# VPAC0_VISS0_ECC_AGGR_0_IVPAC_TOP_0_CFG_SLV_PAR_VPAC_VISS0_S_VBUSP_KSDW_ECC_AGGR_CFG register map
Vendor: Texas Instruments
Peripheral module from a debugger description file (folder am62A).
Registers are 32-bit, access not given, reset 0x0 unless marked. A register's access mark holds for its fields unless they carry their own. Offsets are as the file gives them; lines under a group give offsets from that group; [hi:lo] are bit positions; {n}, {i} and the like mark numbered series; 'fields as' and 'values as' point back to an identical list; <NAME> marks a mode.

## VPAC0_VISS0_ECC_AGGR_0_IVPAC_TOP_0_CFG_SLV_PAR_VPAC_VISS0_S_VBUSP_KSDW_ECC_AGGR_CFG
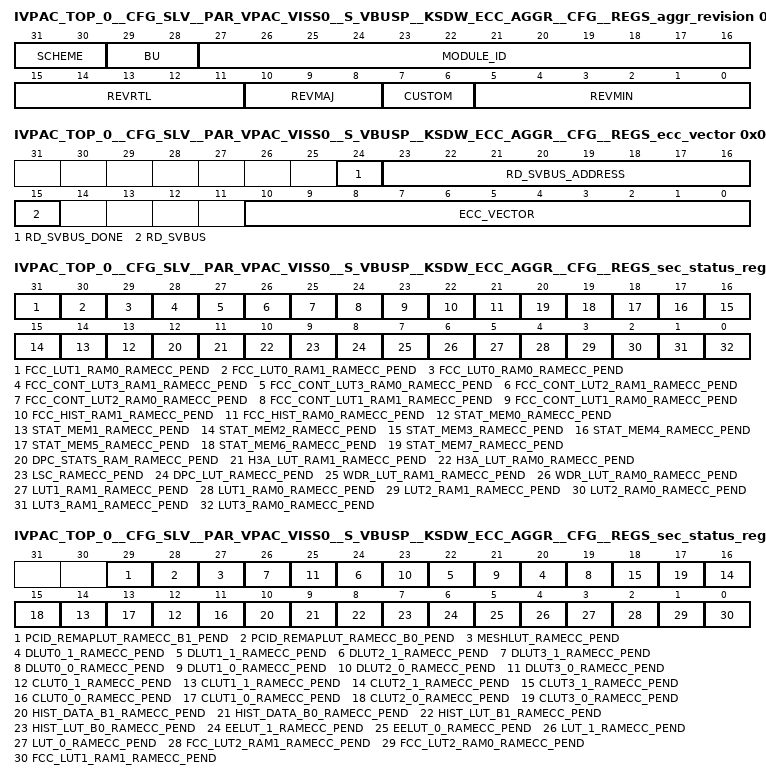
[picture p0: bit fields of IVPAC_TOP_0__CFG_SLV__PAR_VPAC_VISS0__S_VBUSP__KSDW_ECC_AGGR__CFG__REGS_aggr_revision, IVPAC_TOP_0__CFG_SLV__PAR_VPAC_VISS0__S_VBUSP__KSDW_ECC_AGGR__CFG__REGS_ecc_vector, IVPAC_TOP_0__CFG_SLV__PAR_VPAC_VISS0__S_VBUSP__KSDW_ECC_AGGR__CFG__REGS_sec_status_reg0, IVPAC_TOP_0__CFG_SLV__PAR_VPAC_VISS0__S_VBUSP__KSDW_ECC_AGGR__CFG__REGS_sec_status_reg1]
0x00 IVPAC_TOP_0__CFG_SLV__PAR_VPAC_VISS0__S_VBUSP__KSDW_ECC_AGGR__CFG__REGS_aggr_revision ro reset 0x66A03A01 — Revision parameters
  [31:30] SCHEME
  [29:28] BU
  [27:16] MODULE_ID
  [15:11] REVRTL — RTL version
  [10:8] REVMAJ — Major version
  [7:6] CUSTOM — Custom version
  [5:0] REVMIN — Minor version
0x08 IVPAC_TOP_0__CFG_SLV__PAR_VPAC_VISS0__S_VBUSP__KSDW_ECC_AGGR__CFG__REGS_ecc_vector — ECC Vector Register
  [24] RD_SVBUS_DONE — Status to indicate if read on serial VBUS is complete, write of any value will clear this bit. (access R/W1TC)
  [23:16] RD_SVBUS_ADDRESS rw — Read address
  [15] RD_SVBUS — Write 1 to trigger a read on the serial VBUS (access R/W1TS)
  [10:0] ECC_VECTOR rw — Value written to select the corresponding ECC RAM for control or status
0x0C IVPAC_TOP_0__CFG_SLV__PAR_VPAC_VISS0__S_VBUSP__KSDW_ECC_AGGR__CFG__REGS_misc_status ro reset 0x3E — Misc Status
  [10:0] NUM_RAMS — Indicates the number of RAMS serviced by the ECC aggregator
0x10 IVPAC_TOP_0__CFG_SLV__PAR_VPAC_VISS0__S_VBUSP__KSDW_ECC_AGGR__CFG__REGS_reserved_svbus rw — Reference other documents that contain the ECC RAM wrapper and EDC controller serial vbus register sets.
  [31:0] DATA — Serial VBUS register data
0x3C IVPAC_TOP_0__CFG_SLV__PAR_VPAC_VISS0__S_VBUSP__KSDW_ECC_AGGR__CFG__REGS_sec_eoi_reg — EOI Register
  [0] EOI_WR — EOI Register (access R/W1TS)
0x40 IVPAC_TOP_0__CFG_SLV__PAR_VPAC_VISS0__S_VBUSP__KSDW_ECC_AGGR__CFG__REGS_sec_status_reg0 — Interrupt Status Register 0
  [31] FCC_LUT1_RAM0_RAMECC_PEND — Interrupt Pending Status for fcc_lut1_ram0_ramecc_pend (access R/W1TS)
  [30] FCC_LUT0_RAM1_RAMECC_PEND — Interrupt Pending Status for fcc_lut0_ram1_ramecc_pend (access R/W1TS)
  [29] FCC_LUT0_RAM0_RAMECC_PEND — Interrupt Pending Status for fcc_lut0_ram0_ramecc_pend (access R/W1TS)
  [28] FCC_CONT_LUT3_RAM1_RAMECC_PEND — Interrupt Pending Status for fcc_cont_lut3_ram1_ramecc_pend (access R/W1TS)
  [27] FCC_CONT_LUT3_RAM0_RAMECC_PEND — Interrupt Pending Status for fcc_cont_lut3_ram0_ramecc_pend (access R/W1TS)
  [26] FCC_CONT_LUT2_RAM1_RAMECC_PEND — Interrupt Pending Status for fcc_cont_lut2_ram1_ramecc_pend (access R/W1TS)
  [25] FCC_CONT_LUT2_RAM0_RAMECC_PEND — Interrupt Pending Status for fcc_cont_lut2_ram0_ramecc_pend (access R/W1TS)
  [24] FCC_CONT_LUT1_RAM1_RAMECC_PEND — Interrupt Pending Status for fcc_cont_lut1_ram1_ramecc_pend (access R/W1TS)
  [23] FCC_CONT_LUT1_RAM0_RAMECC_PEND — Interrupt Pending Status for fcc_cont_lut1_ram0_ramecc_pend (access R/W1TS)
  [22] FCC_HIST_RAM1_RAMECC_PEND — Interrupt Pending Status for fcc_hist_ram1_ramecc_pend (access R/W1TS)
  [21] FCC_HIST_RAM0_RAMECC_PEND — Interrupt Pending Status for fcc_hist_ram0_ramecc_pend (access R/W1TS)
  [n+13] STAT_MEM{n}_RAMECC_PEND (n=0..7) — Interrupt Pending Status for stat_mem{n}_ramecc_pend (access R/W1TS)
  [12] DPC_STATS_RAM_RAMECC_PEND — Interrupt Pending Status for dpc_stats_ram_ramecc_pend (access R/W1TS)
  [11] H3A_LUT_RAM1_RAMECC_PEND — Interrupt Pending Status for h3a_lut_ram1_ramecc_pend (access R/W1TS)
  [10] H3A_LUT_RAM0_RAMECC_PEND — Interrupt Pending Status for h3a_lut_ram0_ramecc_pend (access R/W1TS)
  [9] LSC_RAMECC_PEND — Interrupt Pending Status for lsc_ramecc_pend (access R/W1TS)
  [8] DPC_LUT_RAMECC_PEND — Interrupt Pending Status for dpc_lut_ramecc_pend (access R/W1TS)
  [7] WDR_LUT_RAM1_RAMECC_PEND — Interrupt Pending Status for wdr_lut_ram1_ramecc_pend (access R/W1TS)
  [6] WDR_LUT_RAM0_RAMECC_PEND — Interrupt Pending Status for wdr_lut_ram0_ramecc_pend (access R/W1TS)
  [5] LUT1_RAM1_RAMECC_PEND — Interrupt Pending Status for lut1_ram1_ramecc_pend (access R/W1TS)
  [4] LUT1_RAM0_RAMECC_PEND — Interrupt Pending Status for lut1_ram0_ramecc_pend (access R/W1TS)
  [3] LUT2_RAM1_RAMECC_PEND — Interrupt Pending Status for lut2_ram1_ramecc_pend (access R/W1TS)
  [2] LUT2_RAM0_RAMECC_PEND — Interrupt Pending Status for lut2_ram0_ramecc_pend (access R/W1TS)
  [1] LUT3_RAM1_RAMECC_PEND — Interrupt Pending Status for lut3_ram1_ramecc_pend (access R/W1TS)
  [0] LUT3_RAM0_RAMECC_PEND — Interrupt Pending Status for lut3_ram0_ramecc_pend (access R/W1TS)
0x44 IVPAC_TOP_0__CFG_SLV__PAR_VPAC_VISS0__S_VBUSP__KSDW_ECC_AGGR__CFG__REGS_sec_status_reg1 — Interrupt Status Register 1
  [29] PCID_REMAPLUT_RAMECC_B1_PEND — Interrupt Pending Status for pcid_remaplut_ramecc_b1_pend (access R/W1TS)
  [28] PCID_REMAPLUT_RAMECC_B0_PEND — Interrupt Pending Status for pcid_remaplut_ramecc_b0_pend (access R/W1TS)
  [27] MESHLUT_RAMECC_PEND — Interrupt Pending Status for meshlut_ramecc_pend (access R/W1TS)
  [2n+20] DLUT{n}_1_RAMECC_PEND (n=0..3) — Interrupt Pending Status for dlut{n}_1_ramecc_pend (access R/W1TS)
  [2n+19] DLUT{n}_0_RAMECC_PEND (n=0..3) — Interrupt Pending Status for dlut{n}_0_ramecc_pend (access R/W1TS)
  [2n+12] CLUT{n}_1_RAMECC_PEND (n=0..3) — Interrupt Pending Status for clut{n}_1_ramecc_pend (access R/W1TS)
  [2n+11] CLUT{n}_0_RAMECC_PEND (n=0..3) — Interrupt Pending Status for clut{n}_0_ramecc_pend (access R/W1TS)
  [10] HIST_DATA_B1_RAMECC_PEND — Interrupt Pending Status for hist_data_b1_ramecc_pend (access R/W1TS)
  [9] HIST_DATA_B0_RAMECC_PEND — Interrupt Pending Status for hist_data_b0_ramecc_pend (access R/W1TS)
  [8] HIST_LUT_B1_RAMECC_PEND — Interrupt Pending Status for hist_lut_b1_ramecc_pend (access R/W1TS)
  [7] HIST_LUT_B0_RAMECC_PEND — Interrupt Pending Status for hist_lut_b0_ramecc_pend (access R/W1TS)
  [6] EELUT_1_RAMECC_PEND — Interrupt Pending Status for eelut_1_ramecc_pend (access R/W1TS)
  [5] EELUT_0_RAMECC_PEND — Interrupt Pending Status for eelut_0_ramecc_pend (access R/W1TS)
  [4] LUT_1_RAMECC_PEND — Interrupt Pending Status for lut_1_ramecc_pend (access R/W1TS)
  [3] LUT_0_RAMECC_PEND — Interrupt Pending Status for lut_0_ramecc_pend (access R/W1TS)
  [2] FCC_LUT2_RAM1_RAMECC_PEND — Interrupt Pending Status for fcc_lut2_ram1_ramecc_pend (access R/W1TS)
  [1] FCC_LUT2_RAM0_RAMECC_PEND — Interrupt Pending Status for fcc_lut2_ram0_ramecc_pend (access R/W1TS)
  [0] FCC_LUT1_RAM1_RAMECC_PEND — Interrupt Pending Status for fcc_lut1_ram1_ramecc_pend (access R/W1TS)
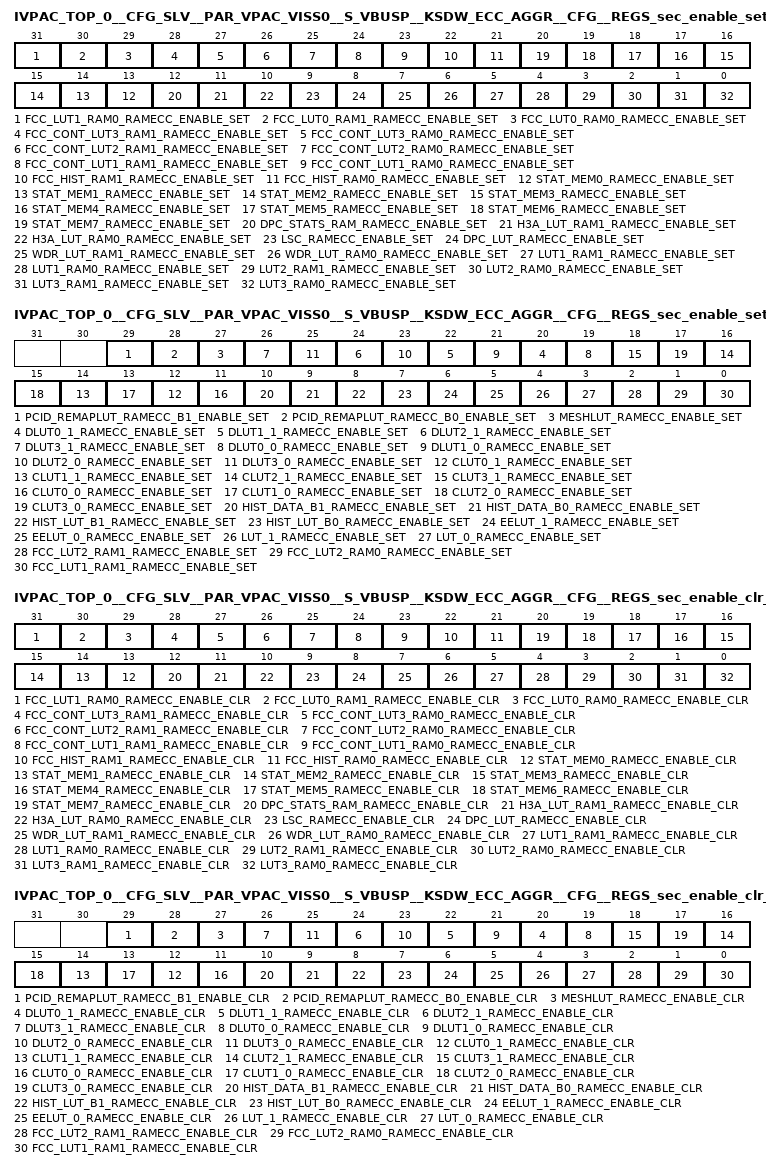
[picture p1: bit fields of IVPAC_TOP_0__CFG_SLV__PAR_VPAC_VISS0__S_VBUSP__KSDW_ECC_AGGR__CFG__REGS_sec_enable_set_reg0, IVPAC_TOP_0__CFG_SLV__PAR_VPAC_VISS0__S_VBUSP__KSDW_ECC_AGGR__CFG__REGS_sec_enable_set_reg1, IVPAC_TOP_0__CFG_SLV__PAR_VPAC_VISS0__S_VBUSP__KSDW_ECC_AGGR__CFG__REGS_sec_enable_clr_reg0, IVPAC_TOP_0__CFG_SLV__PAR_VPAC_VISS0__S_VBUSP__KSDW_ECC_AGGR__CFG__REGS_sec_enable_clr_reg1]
0x80 IVPAC_TOP_0__CFG_SLV__PAR_VPAC_VISS0__S_VBUSP__KSDW_ECC_AGGR__CFG__REGS_sec_enable_set_reg0 — Interrupt Enable Set Register 0
  [31] FCC_LUT1_RAM0_RAMECC_ENABLE_SET — Interrupt Enable Set Register for fcc_lut1_ram0_ramecc_pend (access R/W1TS)
  [30] FCC_LUT0_RAM1_RAMECC_ENABLE_SET — Interrupt Enable Set Register for fcc_lut0_ram1_ramecc_pend (access R/W1TS)
  [29] FCC_LUT0_RAM0_RAMECC_ENABLE_SET — Interrupt Enable Set Register for fcc_lut0_ram0_ramecc_pend (access R/W1TS)
  [28] FCC_CONT_LUT3_RAM1_RAMECC_ENABLE_SET — Interrupt Enable Set Register for fcc_cont_lut3_ram1_ramecc_pend (access R/W1TS)
  [27] FCC_CONT_LUT3_RAM0_RAMECC_ENABLE_SET — Interrupt Enable Set Register for fcc_cont_lut3_ram0_ramecc_pend (access R/W1TS)
  [26] FCC_CONT_LUT2_RAM1_RAMECC_ENABLE_SET — Interrupt Enable Set Register for fcc_cont_lut2_ram1_ramecc_pend (access R/W1TS)
  [25] FCC_CONT_LUT2_RAM0_RAMECC_ENABLE_SET — Interrupt Enable Set Register for fcc_cont_lut2_ram0_ramecc_pend (access R/W1TS)
  [24] FCC_CONT_LUT1_RAM1_RAMECC_ENABLE_SET — Interrupt Enable Set Register for fcc_cont_lut1_ram1_ramecc_pend (access R/W1TS)
  [23] FCC_CONT_LUT1_RAM0_RAMECC_ENABLE_SET — Interrupt Enable Set Register for fcc_cont_lut1_ram0_ramecc_pend (access R/W1TS)
  [22] FCC_HIST_RAM1_RAMECC_ENABLE_SET — Interrupt Enable Set Register for fcc_hist_ram1_ramecc_pend (access R/W1TS)
  [21] FCC_HIST_RAM0_RAMECC_ENABLE_SET — Interrupt Enable Set Register for fcc_hist_ram0_ramecc_pend (access R/W1TS)
  [n+13] STAT_MEM{n}_RAMECC_ENABLE_SET (n=0..7) — Interrupt Enable Set Register for stat_mem{n}_ramecc_pend (access R/W1TS)
  [12] DPC_STATS_RAM_RAMECC_ENABLE_SET — Interrupt Enable Set Register for dpc_stats_ram_ramecc_pend (access R/W1TS)
  [11] H3A_LUT_RAM1_RAMECC_ENABLE_SET — Interrupt Enable Set Register for h3a_lut_ram1_ramecc_pend (access R/W1TS)
  [10] H3A_LUT_RAM0_RAMECC_ENABLE_SET — Interrupt Enable Set Register for h3a_lut_ram0_ramecc_pend (access R/W1TS)
  [9] LSC_RAMECC_ENABLE_SET — Interrupt Enable Set Register for lsc_ramecc_pend (access R/W1TS)
  [8] DPC_LUT_RAMECC_ENABLE_SET — Interrupt Enable Set Register for dpc_lut_ramecc_pend (access R/W1TS)
  [7] WDR_LUT_RAM1_RAMECC_ENABLE_SET — Interrupt Enable Set Register for wdr_lut_ram1_ramecc_pend (access R/W1TS)
  [6] WDR_LUT_RAM0_RAMECC_ENABLE_SET — Interrupt Enable Set Register for wdr_lut_ram0_ramecc_pend (access R/W1TS)
  [5] LUT1_RAM1_RAMECC_ENABLE_SET — Interrupt Enable Set Register for lut1_ram1_ramecc_pend (access R/W1TS)
  [4] LUT1_RAM0_RAMECC_ENABLE_SET — Interrupt Enable Set Register for lut1_ram0_ramecc_pend (access R/W1TS)
  [3] LUT2_RAM1_RAMECC_ENABLE_SET — Interrupt Enable Set Register for lut2_ram1_ramecc_pend (access R/W1TS)
  [2] LUT2_RAM0_RAMECC_ENABLE_SET — Interrupt Enable Set Register for lut2_ram0_ramecc_pend (access R/W1TS)
  [1] LUT3_RAM1_RAMECC_ENABLE_SET — Interrupt Enable Set Register for lut3_ram1_ramecc_pend (access R/W1TS)
  [0] LUT3_RAM0_RAMECC_ENABLE_SET — Interrupt Enable Set Register for lut3_ram0_ramecc_pend (access R/W1TS)
0x84 IVPAC_TOP_0__CFG_SLV__PAR_VPAC_VISS0__S_VBUSP__KSDW_ECC_AGGR__CFG__REGS_sec_enable_set_reg1 — Interrupt Enable Set Register 1
  [29] PCID_REMAPLUT_RAMECC_B1_ENABLE_SET — Interrupt Enable Set Register for pcid_remaplut_ramecc_b1_pend (access R/W1TS)
  [28] PCID_REMAPLUT_RAMECC_B0_ENABLE_SET — Interrupt Enable Set Register for pcid_remaplut_ramecc_b0_pend (access R/W1TS)
  [27] MESHLUT_RAMECC_ENABLE_SET — Interrupt Enable Set Register for meshlut_ramecc_pend (access R/W1TS)
  [2n+20] DLUT{n}_1_RAMECC_ENABLE_SET (n=0..3) — Interrupt Enable Set Register for dlut{n}_1_ramecc_pend (access R/W1TS)
  [2n+19] DLUT{n}_0_RAMECC_ENABLE_SET (n=0..3) — Interrupt Enable Set Register for dlut{n}_0_ramecc_pend (access R/W1TS)
  [2n+12] CLUT{n}_1_RAMECC_ENABLE_SET (n=0..3) — Interrupt Enable Set Register for clut{n}_1_ramecc_pend (access R/W1TS)
  [2n+11] CLUT{n}_0_RAMECC_ENABLE_SET (n=0..3) — Interrupt Enable Set Register for clut{n}_0_ramecc_pend (access R/W1TS)
  [10] HIST_DATA_B1_RAMECC_ENABLE_SET — Interrupt Enable Set Register for hist_data_b1_ramecc_pend (access R/W1TS)
  [9] HIST_DATA_B0_RAMECC_ENABLE_SET — Interrupt Enable Set Register for hist_data_b0_ramecc_pend (access R/W1TS)
  [8] HIST_LUT_B1_RAMECC_ENABLE_SET — Interrupt Enable Set Register for hist_lut_b1_ramecc_pend (access R/W1TS)
  [7] HIST_LUT_B0_RAMECC_ENABLE_SET — Interrupt Enable Set Register for hist_lut_b0_ramecc_pend (access R/W1TS)
  [6] EELUT_1_RAMECC_ENABLE_SET — Interrupt Enable Set Register for eelut_1_ramecc_pend (access R/W1TS)
  [5] EELUT_0_RAMECC_ENABLE_SET — Interrupt Enable Set Register for eelut_0_ramecc_pend (access R/W1TS)
  [4] LUT_1_RAMECC_ENABLE_SET — Interrupt Enable Set Register for lut_1_ramecc_pend (access R/W1TS)
  [3] LUT_0_RAMECC_ENABLE_SET — Interrupt Enable Set Register for lut_0_ramecc_pend (access R/W1TS)
  [2] FCC_LUT2_RAM1_RAMECC_ENABLE_SET — Interrupt Enable Set Register for fcc_lut2_ram1_ramecc_pend (access R/W1TS)
  [1] FCC_LUT2_RAM0_RAMECC_ENABLE_SET — Interrupt Enable Set Register for fcc_lut2_ram0_ramecc_pend (access R/W1TS)
  [0] FCC_LUT1_RAM1_RAMECC_ENABLE_SET — Interrupt Enable Set Register for fcc_lut1_ram1_ramecc_pend (access R/W1TS)
0xC0 IVPAC_TOP_0__CFG_SLV__PAR_VPAC_VISS0__S_VBUSP__KSDW_ECC_AGGR__CFG__REGS_sec_enable_clr_reg0 — Interrupt Enable Clear Register 0
  [31] FCC_LUT1_RAM0_RAMECC_ENABLE_CLR — Interrupt Enable Clear Register for fcc_lut1_ram0_ramecc_pend (access R/W1TC)
  [30] FCC_LUT0_RAM1_RAMECC_ENABLE_CLR — Interrupt Enable Clear Register for fcc_lut0_ram1_ramecc_pend (access R/W1TC)
  [29] FCC_LUT0_RAM0_RAMECC_ENABLE_CLR — Interrupt Enable Clear Register for fcc_lut0_ram0_ramecc_pend (access R/W1TC)
  [28] FCC_CONT_LUT3_RAM1_RAMECC_ENABLE_CLR — Interrupt Enable Clear Register for fcc_cont_lut3_ram1_ramecc_pend (access R/W1TC)
  [27] FCC_CONT_LUT3_RAM0_RAMECC_ENABLE_CLR — Interrupt Enable Clear Register for fcc_cont_lut3_ram0_ramecc_pend (access R/W1TC)
  [26] FCC_CONT_LUT2_RAM1_RAMECC_ENABLE_CLR — Interrupt Enable Clear Register for fcc_cont_lut2_ram1_ramecc_pend (access R/W1TC)
  [25] FCC_CONT_LUT2_RAM0_RAMECC_ENABLE_CLR — Interrupt Enable Clear Register for fcc_cont_lut2_ram0_ramecc_pend (access R/W1TC)
  [24] FCC_CONT_LUT1_RAM1_RAMECC_ENABLE_CLR — Interrupt Enable Clear Register for fcc_cont_lut1_ram1_ramecc_pend (access R/W1TC)
  [23] FCC_CONT_LUT1_RAM0_RAMECC_ENABLE_CLR — Interrupt Enable Clear Register for fcc_cont_lut1_ram0_ramecc_pend (access R/W1TC)
  [22] FCC_HIST_RAM1_RAMECC_ENABLE_CLR — Interrupt Enable Clear Register for fcc_hist_ram1_ramecc_pend (access R/W1TC)
  [21] FCC_HIST_RAM0_RAMECC_ENABLE_CLR — Interrupt Enable Clear Register for fcc_hist_ram0_ramecc_pend (access R/W1TC)
  [n+13] STAT_MEM{n}_RAMECC_ENABLE_CLR (n=0..7) — Interrupt Enable Clear Register for stat_mem{n}_ramecc_pend (access R/W1TC)
  [12] DPC_STATS_RAM_RAMECC_ENABLE_CLR — Interrupt Enable Clear Register for dpc_stats_ram_ramecc_pend (access R/W1TC)
  [11] H3A_LUT_RAM1_RAMECC_ENABLE_CLR — Interrupt Enable Clear Register for h3a_lut_ram1_ramecc_pend (access R/W1TC)
  [10] H3A_LUT_RAM0_RAMECC_ENABLE_CLR — Interrupt Enable Clear Register for h3a_lut_ram0_ramecc_pend (access R/W1TC)
  [9] LSC_RAMECC_ENABLE_CLR — Interrupt Enable Clear Register for lsc_ramecc_pend (access R/W1TC)
  [8] DPC_LUT_RAMECC_ENABLE_CLR — Interrupt Enable Clear Register for dpc_lut_ramecc_pend (access R/W1TC)
  [7] WDR_LUT_RAM1_RAMECC_ENABLE_CLR — Interrupt Enable Clear Register for wdr_lut_ram1_ramecc_pend (access R/W1TC)
  [6] WDR_LUT_RAM0_RAMECC_ENABLE_CLR — Interrupt Enable Clear Register for wdr_lut_ram0_ramecc_pend (access R/W1TC)
  [5] LUT1_RAM1_RAMECC_ENABLE_CLR — Interrupt Enable Clear Register for lut1_ram1_ramecc_pend (access R/W1TC)
  [4] LUT1_RAM0_RAMECC_ENABLE_CLR — Interrupt Enable Clear Register for lut1_ram0_ramecc_pend (access R/W1TC)
  [3] LUT2_RAM1_RAMECC_ENABLE_CLR — Interrupt Enable Clear Register for lut2_ram1_ramecc_pend (access R/W1TC)
  [2] LUT2_RAM0_RAMECC_ENABLE_CLR — Interrupt Enable Clear Register for lut2_ram0_ramecc_pend (access R/W1TC)
  [1] LUT3_RAM1_RAMECC_ENABLE_CLR — Interrupt Enable Clear Register for lut3_ram1_ramecc_pend (access R/W1TC)
  [0] LUT3_RAM0_RAMECC_ENABLE_CLR — Interrupt Enable Clear Register for lut3_ram0_ramecc_pend (access R/W1TC)
0xC4 IVPAC_TOP_0__CFG_SLV__PAR_VPAC_VISS0__S_VBUSP__KSDW_ECC_AGGR__CFG__REGS_sec_enable_clr_reg1 — Interrupt Enable Clear Register 1
  [29] PCID_REMAPLUT_RAMECC_B1_ENABLE_CLR — Interrupt Enable Clear Register for pcid_remaplut_ramecc_b1_pend (access R/W1TC)
  [28] PCID_REMAPLUT_RAMECC_B0_ENABLE_CLR — Interrupt Enable Clear Register for pcid_remaplut_ramecc_b0_pend (access R/W1TC)
  [27] MESHLUT_RAMECC_ENABLE_CLR — Interrupt Enable Clear Register for meshlut_ramecc_pend (access R/W1TC)
  [2n+20] DLUT{n}_1_RAMECC_ENABLE_CLR (n=0..3) — Interrupt Enable Clear Register for dlut{n}_1_ramecc_pend (access R/W1TC)
  [2n+19] DLUT{n}_0_RAMECC_ENABLE_CLR (n=0..3) — Interrupt Enable Clear Register for dlut{n}_0_ramecc_pend (access R/W1TC)
  [2n+12] CLUT{n}_1_RAMECC_ENABLE_CLR (n=0..3) — Interrupt Enable Clear Register for clut{n}_1_ramecc_pend (access R/W1TC)
  [2n+11] CLUT{n}_0_RAMECC_ENABLE_CLR (n=0..3) — Interrupt Enable Clear Register for clut{n}_0_ramecc_pend (access R/W1TC)
  [10] HIST_DATA_B1_RAMECC_ENABLE_CLR — Interrupt Enable Clear Register for hist_data_b1_ramecc_pend (access R/W1TC)
  [9] HIST_DATA_B0_RAMECC_ENABLE_CLR — Interrupt Enable Clear Register for hist_data_b0_ramecc_pend (access R/W1TC)
  [8] HIST_LUT_B1_RAMECC_ENABLE_CLR — Interrupt Enable Clear Register for hist_lut_b1_ramecc_pend (access R/W1TC)
  [7] HIST_LUT_B0_RAMECC_ENABLE_CLR — Interrupt Enable Clear Register for hist_lut_b0_ramecc_pend (access R/W1TC)
  [6] EELUT_1_RAMECC_ENABLE_CLR — Interrupt Enable Clear Register for eelut_1_ramecc_pend (access R/W1TC)
  [5] EELUT_0_RAMECC_ENABLE_CLR — Interrupt Enable Clear Register for eelut_0_ramecc_pend (access R/W1TC)
  [4] LUT_1_RAMECC_ENABLE_CLR — Interrupt Enable Clear Register for lut_1_ramecc_pend (access R/W1TC)
  [3] LUT_0_RAMECC_ENABLE_CLR — Interrupt Enable Clear Register for lut_0_ramecc_pend (access R/W1TC)
  [2] FCC_LUT2_RAM1_RAMECC_ENABLE_CLR — Interrupt Enable Clear Register for fcc_lut2_ram1_ramecc_pend (access R/W1TC)
  [1] FCC_LUT2_RAM0_RAMECC_ENABLE_CLR — Interrupt Enable Clear Register for fcc_lut2_ram0_ramecc_pend (access R/W1TC)
  [0] FCC_LUT1_RAM1_RAMECC_ENABLE_CLR — Interrupt Enable Clear Register for fcc_lut1_ram1_ramecc_pend (access R/W1TC)
0x13C IVPAC_TOP_0__CFG_SLV__PAR_VPAC_VISS0__S_VBUSP__KSDW_ECC_AGGR__CFG__REGS_ded_eoi_reg — EOI Register
  [0] EOI_WR — EOI Register (access R/W1TS)
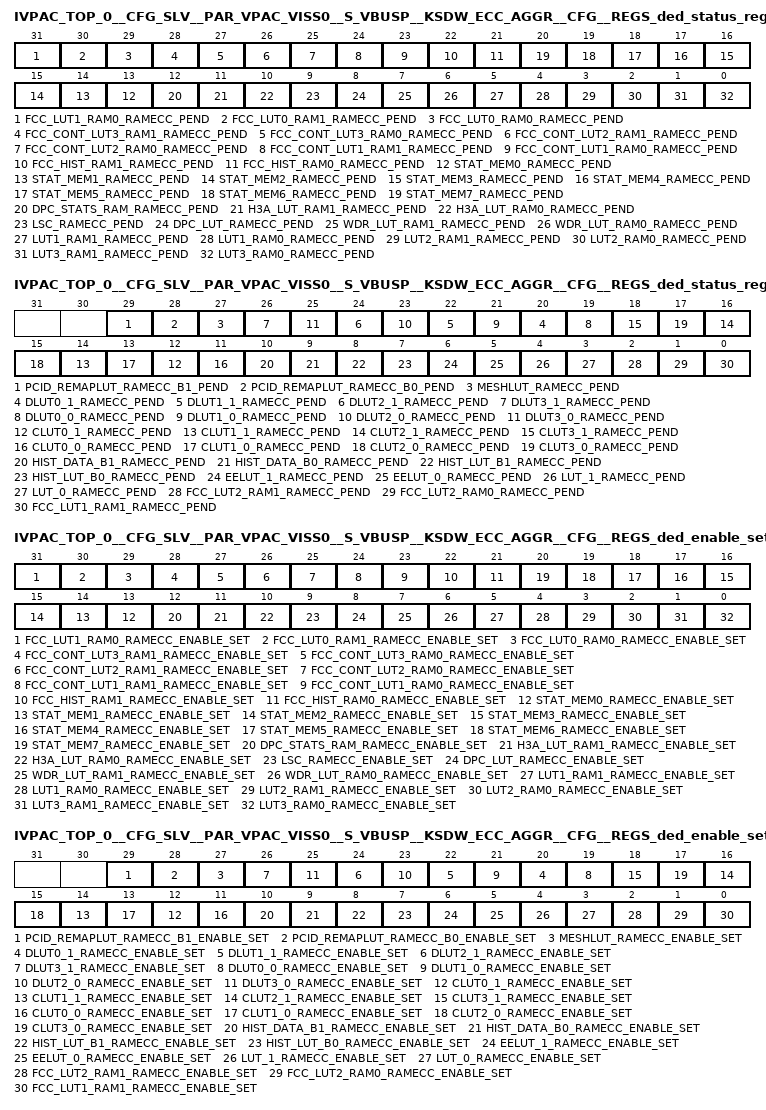
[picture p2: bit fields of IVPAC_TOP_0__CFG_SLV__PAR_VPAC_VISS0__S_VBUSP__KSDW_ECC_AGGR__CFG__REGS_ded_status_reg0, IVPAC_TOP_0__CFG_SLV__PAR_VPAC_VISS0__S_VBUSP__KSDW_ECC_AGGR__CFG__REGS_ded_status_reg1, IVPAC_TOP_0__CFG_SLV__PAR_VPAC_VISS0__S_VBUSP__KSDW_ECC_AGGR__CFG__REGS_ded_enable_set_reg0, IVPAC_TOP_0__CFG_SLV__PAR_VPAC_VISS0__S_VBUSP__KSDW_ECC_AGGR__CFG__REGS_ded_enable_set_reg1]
0x140 IVPAC_TOP_0__CFG_SLV__PAR_VPAC_VISS0__S_VBUSP__KSDW_ECC_AGGR__CFG__REGS_ded_status_reg0 — Interrupt Status Register 0
  fields as IVPAC_TOP_0__CFG_SLV__PAR_VPAC_VISS0__S_VBUSP__KSDW_ECC_AGGR__CFG__REGS_sec_status_reg0
0x144 IVPAC_TOP_0__CFG_SLV__PAR_VPAC_VISS0__S_VBUSP__KSDW_ECC_AGGR__CFG__REGS_ded_status_reg1 — Interrupt Status Register 1
  fields as IVPAC_TOP_0__CFG_SLV__PAR_VPAC_VISS0__S_VBUSP__KSDW_ECC_AGGR__CFG__REGS_sec_status_reg1
0x180 IVPAC_TOP_0__CFG_SLV__PAR_VPAC_VISS0__S_VBUSP__KSDW_ECC_AGGR__CFG__REGS_ded_enable_set_reg0 — Interrupt Enable Set Register 0
  fields as IVPAC_TOP_0__CFG_SLV__PAR_VPAC_VISS0__S_VBUSP__KSDW_ECC_AGGR__CFG__REGS_sec_enable_set_reg0
0x184 IVPAC_TOP_0__CFG_SLV__PAR_VPAC_VISS0__S_VBUSP__KSDW_ECC_AGGR__CFG__REGS_ded_enable_set_reg1 — Interrupt Enable Set Register 1
  fields as IVPAC_TOP_0__CFG_SLV__PAR_VPAC_VISS0__S_VBUSP__KSDW_ECC_AGGR__CFG__REGS_sec_enable_set_reg1
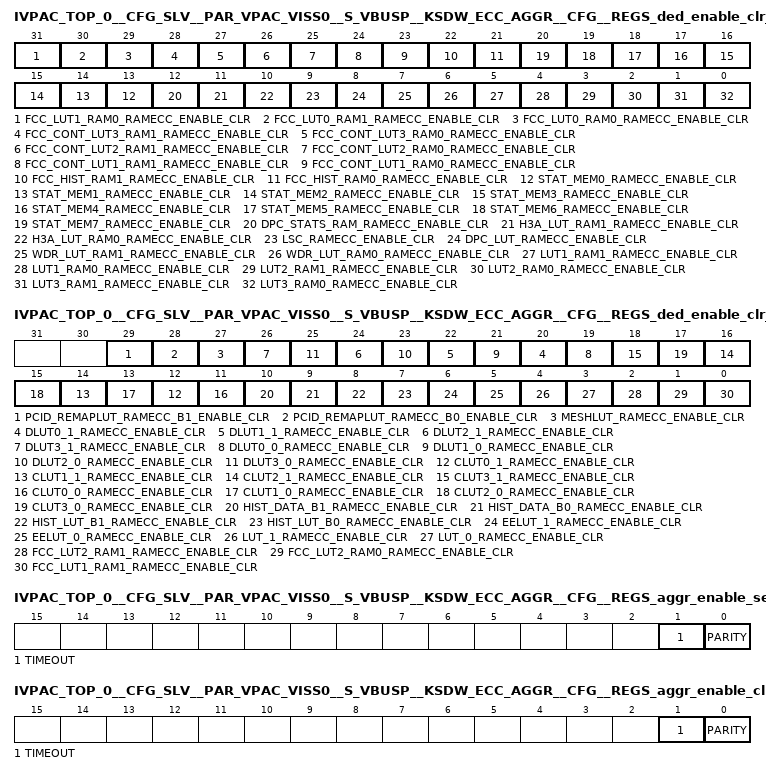
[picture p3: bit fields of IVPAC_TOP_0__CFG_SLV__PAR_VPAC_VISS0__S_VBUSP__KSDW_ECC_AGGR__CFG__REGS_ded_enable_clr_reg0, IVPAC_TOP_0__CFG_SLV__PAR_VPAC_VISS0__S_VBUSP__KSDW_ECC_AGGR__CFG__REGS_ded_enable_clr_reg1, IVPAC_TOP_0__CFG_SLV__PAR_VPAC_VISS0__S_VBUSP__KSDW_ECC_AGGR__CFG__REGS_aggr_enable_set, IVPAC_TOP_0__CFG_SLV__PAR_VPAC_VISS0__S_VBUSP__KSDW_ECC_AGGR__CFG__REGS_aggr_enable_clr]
0x1C0 IVPAC_TOP_0__CFG_SLV__PAR_VPAC_VISS0__S_VBUSP__KSDW_ECC_AGGR__CFG__REGS_ded_enable_clr_reg0 — Interrupt Enable Clear Register 0
  fields as IVPAC_TOP_0__CFG_SLV__PAR_VPAC_VISS0__S_VBUSP__KSDW_ECC_AGGR__CFG__REGS_sec_enable_clr_reg0
0x1C4 IVPAC_TOP_0__CFG_SLV__PAR_VPAC_VISS0__S_VBUSP__KSDW_ECC_AGGR__CFG__REGS_ded_enable_clr_reg1 — Interrupt Enable Clear Register 1
  fields as IVPAC_TOP_0__CFG_SLV__PAR_VPAC_VISS0__S_VBUSP__KSDW_ECC_AGGR__CFG__REGS_sec_enable_clr_reg1
0x200 IVPAC_TOP_0__CFG_SLV__PAR_VPAC_VISS0__S_VBUSP__KSDW_ECC_AGGR__CFG__REGS_aggr_enable_set — AGGR interrupt enable set Register
  [1] TIMEOUT — interrupt enable set for svbus timeout errors (access R/W1TS)
  [0] PARITY — interrupt enable set for parity errors (access R/W1TS)
0x204 IVPAC_TOP_0__CFG_SLV__PAR_VPAC_VISS0__S_VBUSP__KSDW_ECC_AGGR__CFG__REGS_aggr_enable_clr — AGGR interrupt enable clear Register
  [1] TIMEOUT — interrupt enable clear for svbus timeout errors (access R/W1TC)
  [0] PARITY — interrupt enable clear for parity errors (access R/W1TC)
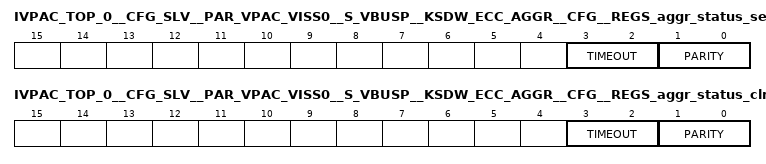
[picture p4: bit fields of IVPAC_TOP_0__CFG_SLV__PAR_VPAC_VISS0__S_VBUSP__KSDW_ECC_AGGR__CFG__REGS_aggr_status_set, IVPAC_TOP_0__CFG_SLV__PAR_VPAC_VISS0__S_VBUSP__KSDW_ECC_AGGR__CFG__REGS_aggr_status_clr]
0x208 IVPAC_TOP_0__CFG_SLV__PAR_VPAC_VISS0__S_VBUSP__KSDW_ECC_AGGR__CFG__REGS_aggr_status_set — AGGR interrupt status set Register
  [3:2] TIMEOUT — interrupt status set for svbus timeout errors (access R/WI)
  [1:0] PARITY — interrupt status set for parity errors (access R/WI)
0x20C IVPAC_TOP_0__CFG_SLV__PAR_VPAC_VISS0__S_VBUSP__KSDW_ECC_AGGR__CFG__REGS_aggr_status_clr — AGGR interrupt status clear Register
  [3:2] TIMEOUT — interrupt status clear for svbus timeout errors (access R/WD)
  [1:0] PARITY — interrupt status clear for parity errors (access R/WD)
